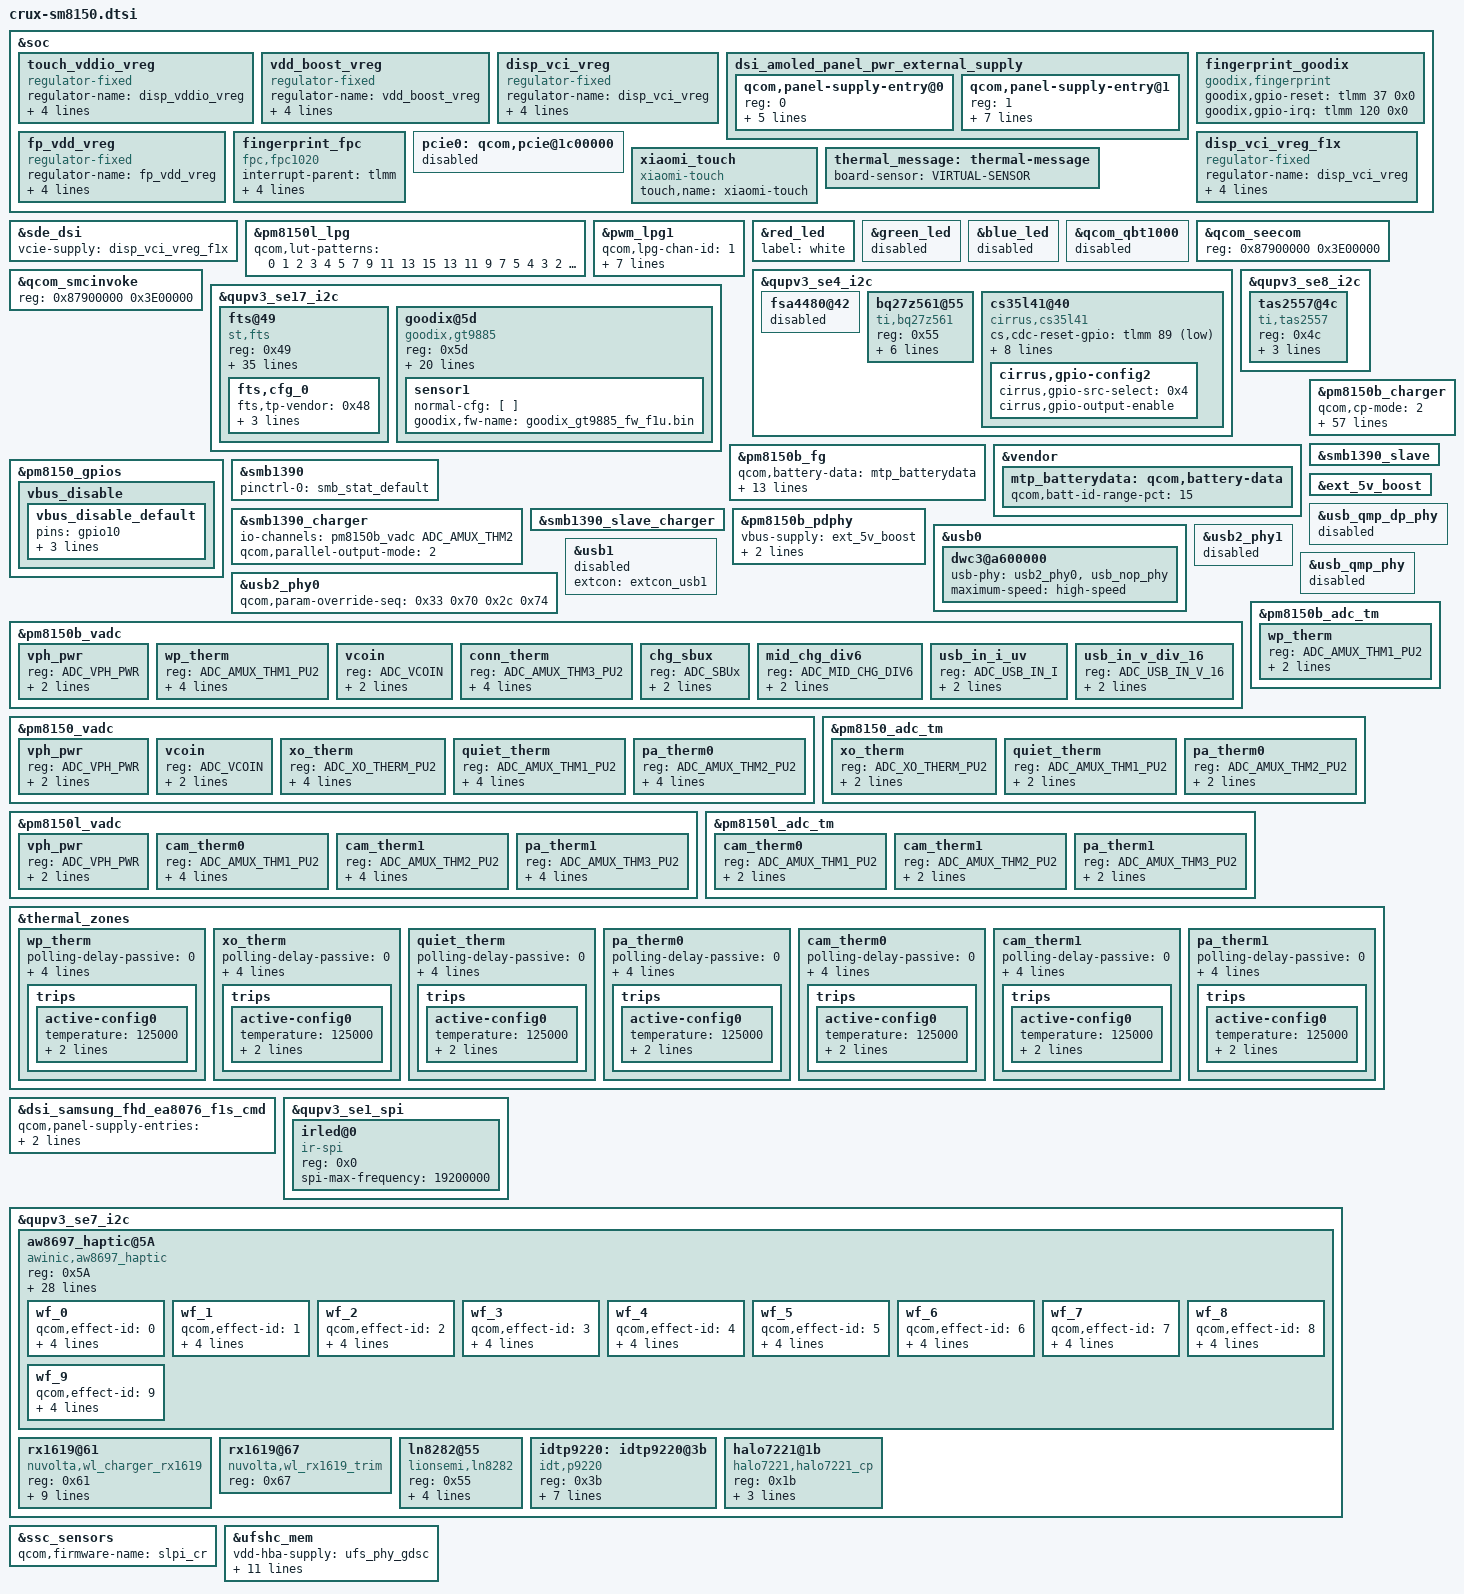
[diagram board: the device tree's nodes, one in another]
/*
this file is for attribution only of andromeda
And public attribution of xiaomi platforms(like F1X and so and)
*/

#include "crux-pinctrl.dtsi"
#include "xiaomi-sdx50-sm8150-common.dtsi"

#include "crux-sm8150-camera-sensor-mtp.dtsi"

&soc {
	touch_vddio_vreg: touch_vddio_vreg {
		compatible = "regulator-fixed";
		regulator-name = "disp_vddio_vreg";
		startup-delay-us = <4000>;
		enable-active-high;
		regulator-boot-on;
		gpio = <&tlmm 31 0>;
	 };
	vdd_boost_vreg: vdd_boost_vreg {
		compatible = "regulator-fixed";
		regulator-name = "vdd_boost_vreg";
		startup-delay-us = <4000>;
		enable-active-high;
		regulator-always-on;
		gpio = <&pm8150b_gpios 5 0>;
	 };
	disp_vci_vreg: disp_vci_vreg {
		compatible = "regulator-fixed";
		regulator-name = "disp_vci_vreg";
		start-delay-us = <4000>;
		enable-active-high;
		regulator-boot-on;
		gpio = <&tlmm 7 0>;
	};

	dsi_amoled_panel_pwr_external_supply: dsi_amoled_panel_pwr_external_supply {
		#address-cells = <1>;
		#size-cells = <0>;

		qcom,panel-supply-entry@0 {
			reg = <0>;
			qcom,supply-name = "vddio";
			qcom,supply-min-voltage = <1800000>;
			qcom,supply-max-voltage = <1800000>;
			qcom,supply-enable-load = <62000>;
			qcom,supply-disable-load = <80>;
			//qcom,supply-post-on-sleep = <20>;
		};

		qcom,panel-supply-entry@1 {
			reg = <1>;
			qcom,supply-name = "vcie";
			qcom,supply-min-voltage = <3000000>;
			qcom,supply-max-voltage = <3000000>;
			qcom,supply-enable-load = <62000>;
			qcom,supply-disable-load = <80>;
			qcom,supply-post-on-sleep = <10>;
			qcom,supply-pre-off-sleep = <10>;
		};
	};
	fingerprint_goodix {
		compatible = "goodix,fingerprint";
		goodix,gpio-reset = <&tlmm 37 0x0>;
		goodix,gpio-irq = <&tlmm 120 0x0>;
		/* fp-gpio-pwr = <&tlmm 125 0>; */
		status = "ok";
	};
	fp_vdd_vreg: fp_vdd_vreg {
		compatible = "regulator-fixed";
		regulator-name = "fp_vdd_vreg";
		startup-delay-us = <4000>;
		enable-active-high;
		gpio = <&tlmm 125 0>;
		regulator-always-on;
	};
	fingerprint_fpc {
		status = "ok";
		compatible = "fpc,fpc1020";
		interrupt-parent = <&tlmm>;
		interrupts = <118 0x0>;
		fpc,gpio_irq = <&tlmm 118 0x0>;
		/* fpc,enable-on-boot; */
		/* fpc,enable-wakeup;  */

		pinctrl-names = "fpc1020_reset_reset",
			"fpc1020_reset_active";

		pinctrl-0 = <&msm_gpio_119>;
		pinctrl-1 = <&msm_gpio_119_output_high>;
	};
	pcie0: qcom,pcie@1c00000 {
		status = "disabled";
	};

	disp_vci_vreg_f1x: disp_vci_vreg_f1x {
		compatible = "regulator-fixed";
		regulator-name = "disp_vci_vreg";
		start-delay-us = <4000>;
		enable-active-high;
		regulator-boot-on;
		gpio = <&tlmm 21 0>;
	};
	xiaomi_touch {
		compatible = "xiaomi-touch";
		status = "ok";
		touch,name = "xiaomi-touch";
	};
	thermal_message: thermal-message {
		board-sensor = "VIRTUAL-SENSOR";
	};
};

&sde_dsi {
	vcie-supply = <&disp_vci_vreg_f1x>;
};

&pm8150l_lpg {
	qcom,lut-patterns = <0 1 2 3 4 5 7 9 11 13 15
				13 11 9 7 5 4 3 2 1 0>;
};

&pwm_lpg1 {
	qcom,lpg-chan-id = <1>;
	qcom,ramp-step-ms = <100>;
	qcom,ramp-pause-hi-count = <2>;
	qcom,ramp-pause-lo-count = <2>;
	qcom,ramp-low-index = <0>;
	qcom,ramp-high-index = <20>;
	qcom,ramp-from-low-to-high;
	qcom,ramp-pattern-repeat;
};

&red_led {
	label = "white";
};

&green_led {
	status = "disabled";
};

&blue_led {
	status = "disabled";
};

&qcom_qbt1000 {
	status = "disabled";
};

&qcom_seecom {
	reg = <0x87900000 0x3E00000>;
};

&qcom_smcinvoke {
	reg = <0x87900000 0x3E00000>;
};

&qupv3_se4_i2c {
	status = "ok";

	fsa4480@42 {
		status = "disabled";
	};
};

&qupv3_se8_i2c {
	status = "ok";
	/*smart PA*/
	tas2557@4c{
		compatible = "ti,tas2557";
		reg = <0x4c>;
		//ti,cdc-reset-gpio = <&tlmm 59 0>;
		ti,irq-gpio = <&tlmm 115 0>;
		ti,i2s-bits = <16>;
		ti,bypass-tmax = <0>;
	};
};

&qupv3_se17_i2c {
	status = "ok";
	fts@49 {
		compatible = "st,fts";
		reg = <0x49>;
		interrupt-parent = <&tlmm>;
		interrupts = <122 0x2008>;
		pinctrl-names = "pmx_ts_active", "pmx_ts_suspend";
		pinctrl-0 = <&ts_active>;
		pinctrl-1 = <&ts_int_suspend &ts_reset_suspend>;
		avdd-supply = <&pm8150l_l1>;
		vdd-supply = <&touch_vddio_vreg>;
		fts,pwr-reg-name = "avdd";
		fts,bus-reg-name = "vdd";
		fts,irq-gpio = <&tlmm 122 0x2008>;
		fts,irq-gpio-name = "fts_irq";
		fts,reset-gpio-enable;
		fts,reset-gpio = <&tlmm 12 0x00>;
		fts,reset-gpio-name = "fts_rst";
		fts,irq-flags = <0x2008>; /* IRQF_ONESHOT | IRQF_TRIGGER_LOW */
		fts,x-max = <1080>;
		fts,y-max = <2340>;
		fts,default-fw-name = "st_fts_f1x.ftb";
		fts,config-array-size = <1>;
		fts,dump-click-count;
		fts,touch-up-threshold-min = <40>;
		fts,touch-up-threshold-max = <120>;
		fts,touch-up-threshold-def = <80>;
		fts,touch-tolerance-min = <5>;
		fts,touch-tolerance-max = <35>;
		fts,touch-tolerance-def = <25>;
		fts,edgefilter-leftrigt-def = <45>;
		fts,edgefilter-topbottom-def = <0>;
		fts,edgefilter-top-ingamemode = <65>;
		fts,edgefilter-bottom-ingamemode = <0>;
		fts,edgefilter-area-step1 = <100>;
		fts,edgefilter-area-step2 = <150>;
		fts,edgefilter-area-step3 = <250>;
		fts,touch-idletime-min = <0>;
		fts,touch-idletime-max = <12750>;
		fts,touch-idletime-def = <12450>;
		fts,cfg_0 {
			fts,tp-vendor = <0x48>;
			fts,fw-name = "st_fts_f1x.ftb";
			fts,limit-name = "stm_fts_production_limits.csv";
			fts,clicknum-file-name = "fts+sdc";
		};
	};
	goodix@5d {
		compatible = "goodix,gt9885";
		reg = <0x5d>;
		status = "ok";
		interrupt-parent = <&tlmm>;
		interrupts = <122 0x2800>;
		vtouch-source-supply = <&vdd_boost_vreg>;
		vtouch-supply = <&touch_vddio_vreg>;
		iotouch-supply = <&pm8150l_l1>;
		vtouch-load = <600000>;
		pinctrl-names = "pmx_ts_active","pmx_ts_suspend";
		pinctrl-0 = <&ts_active>;
		pinctrl-1 = <&ts_int_suspend &ts_reset_suspend>;
		goodix,reset-gpio = <&tlmm 12 0x0>;
		goodix,irq-gpio = <&tlmm 122 0x2800>;
		goodix,irq-flags = <2>; /* 1:trigger rising, 2:trigger falling;*/
		goodix,panel-max-id = <10>;
		goodix,panel-max-x = <1079>;
		goodix,panel-max-y = <2339>;
		goodix,panel-max-w = <127>;
		goodix,panel-max-p = <127>;
		goodix,panel-max-fod = <127>;
	/*	goodix,panel-key-map = <158 172 217>; */ /*KEY_BACK, KEY_HOMEPAGE, KEY_SEARCH*/
		goodix,power-on-delay-us = <300000>; /*300ms*/
		goodix,power-off-delay-us = <5000>;
		goodix,cfg-name = "goodix_gt9885_cfg_f1u.bin";
	/*	goodix,swap-axis; */
	/*	goodix,pen-enable; */
	/*	goodix,key-of-pen = <331 332>; */ /*BTN_STYLUS, BTN_STYLUS2*/
		sensor1 {
				normal-cfg = [
				];
				goodix,fw-name = "goodix_gt9885_fw_f1u.bin";
		};
	};
};

&pm8150b_fg {
	qcom,battery-data = <&mtp_batterydata>;
	qcom,rapid-soc-dec-en;
	qcom,fg-sys-term-current = <(-300)>;
	qcom,fg-cutoff-voltage = <3400>;
	qcom,fg-cutoff-current = <200>;
	qcom,fg-empty-voltage = <3100>;
	qcom,fg-batt-temp-delta = <6>;
	qcom,fg-force-load-profile;
	/* ESR fast calibration */
	qcom,fg-esr-timer-chg-fast = <0 7>;
	qcom,fg-esr-timer-dischg-fast = <0 7>;
	qcom,fg-esr-timer-chg-slow = <0 96>;
	qcom,fg-esr-timer-dischg-slow = <0 96>;
	qcom,fg-esr-cal-soc-thresh = <26 230>;
	qcom,fg-esr-cal-temp-thresh = <10 40>;
};

&vendor {
	mtp_batterydata: qcom,battery-data {
		qcom,batt-id-range-pct = <15>;
		#include "batterydata-F1-atl-3300mah.dtsi"
		#include "batterydata-F1-coslight-3300mah.dtsi"
		#include "fg-gen4-batterydata-alium-3600mah.dtsi"
	};
};

&pm8150_gpios {
	vbus_disable {
		vbus_disable_default: vbus_disable_default {
			pins = "gpio10";
			function = "normal";
			output-low;
			power-source = <1>;	/* 1.8V input supply */
		};
	};
};

&pm8150b_charger {
	qcom,cp-mode = <2>;
	qcom,sec-charger-config = <1>;
	qcom,usb-icl-ua = <4000000>;
	qcom,fcc-max-ua = <8000000>;
	qcom,fv-max-uv = <4480000>;
	qcom,dc-icl-ua = <500000>;
	qcom,auto-recharge-vbat-mv = <4380>;
	qcom,step-charging-enable;
	qcom,sw-jeita-enable;
	qcom,chg-term-src = <1>;
	qcom,chg-term-current-ma = <(-220)>;
	qcom,chg-term-base-current-ma = <50>;
	qcom,thermal-mitigation = <3000000 2800000 2600000 2400000 2200000 2100000 2000000
				   1800000 1600000 1500000 1400000 1200000 1000000 900000
				   800000 500000>;
	qcom,thermal-mitigation-icl
				= <2800000 2700000 2600000 2400000 2400000 2400000 2400000
				   2400000 2400000 2100000 1900000 1700000 1500000 1300000
				   1000000 750000>;
	qcom,thermal-mitigation-dcp
				= <1800000 1800000 1800000 1800000 1800000 1800000 1800000
				   1800000 1800000 1700000 1600000 1400000 1200000 1100000
				   1100000 1000000>;
	qcom,thermal-mitigation-qc2
				= <1500000 1500000 1500000 1500000 1450000 1400000 1350000
				   1300000 1300000 1200000 1000000 900000 850000 750000
				   650000 500000>;
	qcom,thermal-fcc-qc3-normal
				= <3200000 3000000 2800000 2600000 2500000 2400000 2300000
				   2200000 2100000 1800000 1600000 1400000 1200000 1000000
				   750000 750000>;
	qcom,thermal-fcc-qc3-cp
				= <3600000 3600000 3600000 3600000 3200000 3200000 3200000
				   3200000 3100000 2800000 2400000 2200000 2000000 1300000
				   750000 700000>;
	qcom,thermal-fcc-qc3-classb-cp
				= <4800000 4700000 4600000 4500000 4400000 4200000 4200000
				   4200000 4000000 3600000 3400000 3200000 3000000 2200000
				   1000000 700000>;
	qcom,thermal-mitigation-pd-base
				= <4000000 3600000 3200000 2800000 2800000 2800000 2800000
				   2800000 2800000 2400000 2400000 2000000 1600000 1300000
				   1000000 500000>;
	qcom,thermal-fcc-pps-cp
				= <8000000 7500000 7000000 6500000 6000000 5500000 5350000
				   4500000 4000000 3500000 3000000 3000000 3000000 2000000
				   1500000 100000>;
	qcom,thermal-mitigation-dc
				= <3100000 2200000 1800000 1600000 1400000 1200000 1100000
				   1000000 900000  800000  700000  600000  500000  400000
				   300000  200000>;
	qcom,thermal-mitigation-epp
				= <1200000 1200000 1200000 1100000 1100000 1000000 1000000
				   1000000 900000  700000  700000  600000  500000  400000
				   300000  200000>;
	qcom,thermal-mitigation-bpp-qc3
				= <1400000 1300000 1200000 1200000 1100000 1000000 900000
				   800000  700000  700000  700000  600000  500000  400000
				   300000  200000>;
	qcom,thermal-mitigation-bpp-qc2
				= <1100000 1100000 1100000 1100000 1100000 1000000 1000000
				   1000000 700000  700000  700000  600000  500000  400000
				   300000  200000>;
	qcom,thermal-mitigation-bpp
				= <700000 700000 700000 700000 700000 700000 700000
				   700000 700000  600000  600000  500000  400000 300000
				   200000  200000>;
	qcom,thermal-mitigation-dc-20w
				= <2200000 1400000 1300000 1200000 700000 600000 500000
				   400000 400000  400000  400000  400000  400000  400000
				   400000  400000>;

	io-channels = <&pm8150b_vadc ADC_MID_CHG_DIV6>,
		      <&pm8150b_vadc ADC_USB_IN_V_16>,
		      <&pm8150b_vadc ADC_USB_IN_I>,
		      <&pm8150b_vadc ADC_SBUx>,
		      <&pm8150b_vadc ADC_VPH_PWR>,
		      <&pm8150b_vadc ADC_CHG_TEMP>,
		      <&pm8150b_vadc ADC_AMUX_THM3_PU2>;

	io-channel-names = "mid_voltage",
			   "usb_in_voltage",
			   "usb_in_current",
			   "sbux_res",
			   "vph_voltage",
			   "chg_temp",
			   "conn_therm";

	qcom,battery-data = <&mtp_batterydata>;
	dpdm-supply = <&usb2_phy0>;
	qcom,distinguish-qc-class-ab;
	qcom,wd-bark-time-secs = <16>;
	qcom,support-wireless;
	qcom,support-conn-therm;
	qcom,support-ext-fg;

	vbus-disable-gpio = <&pm8150_gpios 10 GPIO_ACTIVE_HIGH>;

	pinctrl-names = "default";
	pinctrl-0 = <&vbus_disable_default>;
};

&smb1390 {
	pinctrl-names = "default";
	pinctrl-0 = <&smb_stat_default>;
	status = "ok";
};

&smb1390_charger {
	io-channels = <&pm8150b_vadc ADC_AMUX_THM2>;
	io-channel-names = "smb1390_therm";
	qcom,parallel-output-mode = <2>;
	status = "ok";
};

&smb1390_slave {
	status = "ok";
};

&smb1390_slave_charger {
	status = "ok";
};



&ext_5v_boost {
	status = "ok";
};

&pm8150b_pdphy {
	vbus-supply = <&ext_5v_boost>;
	mi,pd_curr_limit = <1>;
	mi,pd_max_curr_limit = <4000000>;
};

&usb0 {
	dwc3@a600000 {
		usb-phy = <&usb2_phy0>, <&usb_nop_phy>;
		maximum-speed = "high-speed";
	};
};

&usb2_phy0 {
	qcom,param-override-seq =
		<0x33 0x70
		 0x2c 0x74>;
};

&usb_qmp_dp_phy {
	status = "disabled";
};

&usb1 {
	extcon = <&extcon_usb1>;
	status = "disabled";
};

&usb2_phy1 {
	status = "disabled";
};

&usb_qmp_phy {
	status = "disabled";
};

&pm8150b_vadc {
	vph_pwr {
		reg = <ADC_VPH_PWR>;
		label = "vph_pwr";
		qcom,pre-scaling = <1 3>;
	};

	wp_therm {
		reg = <ADC_AMUX_THM1_PU2>;
		label = "wp_therm";
		qcom,ratiometric;
		qcom,hw-settle-time = <200>;
		qcom,pre-scaling = <1 1>;
	};

	vcoin {
		reg = <ADC_VCOIN>;
		label = "vcoin";
		qcom,pre-scaling = <1 3>;
	};

	conn_therm {
		reg = <ADC_AMUX_THM3_PU2>;
		label = "conn_therm";
		qcom,ratiometric;
		qcom,hw-settle-time = <200>;
		qcom,pre-scaling = <1 1>;
	};

	chg_sbux {
		reg = <ADC_SBUx>;
		label = "chg_sbux";
		qcom,pre-scaling = <1 3>;
	};

	mid_chg_div6 {
		reg = <ADC_MID_CHG_DIV6>;
		label = "chg_mid";
		qcom,pre-scaling = <1 6>;
	};

	usb_in_i_uv {
		reg = <ADC_USB_IN_I>;
		label = "usb_in_i_uv";
		qcom,pre-scaling = <1 1>;
	};

	usb_in_v_div_16 {
		reg = <ADC_USB_IN_V_16>;
		label = "usb_in_v_div_16";
		qcom,pre-scaling = <1 16>;
	};
};

&pm8150_vadc {
	vph_pwr {
		reg = <ADC_VPH_PWR>;
		label = "vph_pwr";
		qcom,pre-scaling = <1 3>;
	};

	vcoin {
		reg = <ADC_VCOIN>;
		label = "vcoin";
		qcom,pre-scaling = <1 3>;
	};

	xo_therm {
		reg = <ADC_XO_THERM_PU2>;
		label = "xo_therm";
		qcom,ratiometric;
		qcom,hw-settle-time = <200>;
		qcom,pre-scaling = <1 1>;
	};

	quiet_therm {
		reg = <ADC_AMUX_THM1_PU2>;
		label = "quiet_therm";
		qcom,ratiometric;
		qcom,hw-settle-time = <200>;
		qcom,pre-scaling = <1 1>;
	};

	pa_therm0 {
		reg = <ADC_AMUX_THM2_PU2>;
		label = "pa_therm0";
		qcom,ratiometric;
		qcom,hw-settle-time = <200>;
		qcom,pre-scaling = <1 1>;
	};
};

&pm8150l_vadc {
	vph_pwr {
		reg = <ADC_VPH_PWR>;
		label = "vph_pwr";
		qcom,pre-scaling = <1 3>;
	};

	cam_therm0 {
		reg = <ADC_AMUX_THM1_PU2>;
		label = "cam_therm0";
		qcom,ratiometric;
		qcom,hw-settle-time = <200>;
		qcom,pre-scaling = <1 1>;
	};

	cam_therm1 {
		reg = <ADC_AMUX_THM2_PU2>;
		label = "cam_therm1";
		qcom,ratiometric;
		qcom,hw-settle-time = <200>;
		qcom,pre-scaling = <1 1>;
	};

	pa_therm1 {
		reg = <ADC_AMUX_THM3_PU2>;
		label = "pa_therm1";
		qcom,ratiometric;
		qcom,hw-settle-time = <200>;
		qcom,pre-scaling = <1 1>;
	};
};

&pm8150b_adc_tm {
	wp_therm {
		reg = <ADC_AMUX_THM1_PU2>;
		qcom,ratiometric;
		qcom,hw-settle-time = <200>;
	};
};

&pm8150_adc_tm {
	xo_therm {
		reg = <ADC_XO_THERM_PU2>;
		qcom,ratiometric;
		qcom,hw-settle-time = <200>;
	};
	quiet_therm {
		reg = <ADC_AMUX_THM1_PU2>;
		qcom,ratiometric;
		qcom,hw-settle-time = <200>;
	};

	pa_therm0 {
		reg = <ADC_AMUX_THM2_PU2>;
		qcom,ratiometric;
		qcom,hw-settle-time = <200>;
	};
};

&pm8150l_adc_tm {
	cam_therm0 {
		reg = <ADC_AMUX_THM1_PU2>;
		qcom,ratiometric;
		qcom,hw-settle-time = <200>;
	};

	cam_therm1 {
		reg = <ADC_AMUX_THM2_PU2>;
		qcom,ratiometric;
		qcom,hw-settle-time = <200>;
	};

	pa_therm1 {
		reg = <ADC_AMUX_THM3_PU2>;
		qcom,ratiometric;
		qcom,hw-settle-time = <200>;
	};
};

&thermal_zones {
	wp_therm {
		polling-delay-passive = <0>;
		polling-delay = <0>;
		thermal-governor = "user_space";
		thermal-sensors = <&pm8150b_adc_tm ADC_AMUX_THM1_PU2>;
		trips {
			active-config0 {
				temperature = <125000>;
				hysteresis = <1000>;
				type = "passive";
			};
		};
	};

	xo_therm {
		polling-delay-passive = <0>;
		polling-delay = <0>;
		thermal-governor = "user_space";
		thermal-sensors = <&pm8150_adc_tm ADC_XO_THERM_PU2>;
		trips {
			active-config0 {
				temperature = <125000>;
				hysteresis = <1000>;
				type = "passive";
			};
		};
	};

	quiet_therm {
		polling-delay-passive = <0>;
		polling-delay = <0>;
		thermal-governor = "user_space";
		thermal-sensors = <&pm8150_adc_tm ADC_AMUX_THM1_PU2>;
		trips {
			active-config0 {
				temperature = <125000>;
				hysteresis = <1000>;
				type = "passive";
			};
		};
	};

	pa_therm0 {
		polling-delay-passive = <0>;
		polling-delay = <0>;
		thermal-governor = "user_space";
		thermal-sensors = <&pm8150_adc_tm ADC_AMUX_THM2_PU2>;
		trips {
			active-config0 {
				temperature = <125000>;
				hysteresis = <1000>;
				type = "passive";
			};
		};
	};

	cam_therm0 {
		polling-delay-passive = <0>;
		polling-delay = <0>;
		thermal-governor = "user_space";
		thermal-sensors = <&pm8150l_adc_tm ADC_AMUX_THM1_PU2>;
		trips {
			active-config0 {
				temperature = <125000>;
				hysteresis = <1000>;
				type = "passive";
			};
		};
	};

	cam_therm1 {
		polling-delay-passive = <0>;
		polling-delay = <0>;
		thermal-governor = "user_space";
		thermal-sensors = <&pm8150l_adc_tm ADC_AMUX_THM2_PU2>;
		trips {
			active-config0 {
				temperature = <125000>;
				hysteresis = <1000>;
				type = "passive";
			};
		};
	};

	pa_therm1 {
		polling-delay-passive = <0>;
		polling-delay = <0>;
		thermal-governor = "user_space";
		thermal-sensors = <&pm8150l_adc_tm ADC_AMUX_THM3_PU2>;
		trips {
			active-config0 {
				temperature = <125000>;
				hysteresis = <1000>;
				type = "passive";
			};
		};
	};
};

&qupv3_se4_i2c {
	status = "ok";
	bq27z561@55 {
		compatible = "ti,bq27z561";
		reg = <0x55>;
		bq,charge-full-design = <4000000>;
		bq,recharge-voltage   = <4380>;
		bq,soc_decimal_rate = <
			0  38
			10 35
			20 33
			30 33
			40 33
			50 33
			60 33
			70 30
			80 25
			90 20
			95 10
			99  5 >;
		bq,cold_thermal_seq = <
			1      0  100 1700
			2  (-300)   0 1000 >;
	};

	fsa4480@42 {
		status = "disabled";
	};

	cs35l41@40 {
		#sound-dai-cells = <1>;
		compatible = "cirrus,cs35l41";
		cs,cdc-reset-gpio = <&tlmm 89 0x01>;
		reg = <0x40>;
		pinctrl-names = "cs35l41_irq_default";
		pinctrl-0 = <&cs35l41_int_default>;
		interrupt-parent = <&tlmm>;
		interrupts = <10 8>;

		cirrus,temp-warn_threshold = <3>;
		cirrus,boost-peak-milliamp = <4000>;
		cirrus,boost-ind-nanohenry = <1000>;
		cirrus,boost-cap-microfarad = <15>;
		cirrus,gpio-config2 {
			cirrus,gpio-src-select = <0x4>;
			cirrus,gpio-output-enable;
		};
		/*
		VA-supply = <&dummy_vreg>;
		VP-supply = <&dummy_vreg>;
		interrupt-parent = <&tlmm>;
		interrupts = <11 8>;
		reset-gpios = <&tlmm 7 0x01>;
		VA-supply = <&pm8998_s4>;
		VP-supply = <&audio_vsys>;
		cirrus,boost-peak-milliamp = <4500>;
		cirrus,boost-ind-nanohenry = <1000>;
		cirrus,boost-cap-microfarad = <15>;
		cirrus,gpio-config2 {
			cirrus,gpio-src-select = <0x4>;
			cirrus,gpio-output-enable;
		};
		*/
	};
};

&dsi_samsung_fhd_ea8076_f1s_cmd {
	qcom,panel-supply-entries = <&dsi_amoled_panel_pwr_external_supply>;
	/* IRQF_ONESHOT | IRQF_TRIGGER_FALLING */
	qcom,esd-err-irq-gpio = <&tlmm 101 0x2002>;
};

//&dsi_visionox_fhd_rm692a9_f1u_cmd {
//	qcom,panel-supply-entries = <&dsi_amoled_panel_pwr_external_supply>;
	/* IRQF_ONESHOT | IRQF_TRIGGER_FALLING */
//	qcom,esd-err-irq-gpio = <&tlmm 101 0x2002>;
//};

&qupv3_se1_spi {
	status = "ok";
	irled@0 {
		compatible = "ir-spi";
		reg = <0x0>;
		status = "ok";
		spi-max-frequency = <19200000>;
	};
};

&qupv3_se7_i2c {
	status = "ok";
	aw8697_haptic@5A {
		compatible = "awinic,aw8697_haptic";
		reg = <0x5A>;
		reset-gpio = <&tlmm 6 0>;
		irq-gpio = <&tlmm 27 0>;
		vib_mode = < 0 >;   /*mode:   RAM mode->0; CONT mode -> 1*/
		vib_f0_pre = < 1700 >;
		vib_f0_cali_percen = < 7 >;
		vib_cont_drv_lev = < 88 >;
		vib_cont_drv_lvl_ov = < 88 >;
		vib_cont_td = < 0xf06c >;
		vib_cont_zc_thr = < 0x08f8 >;  /*hq 0x08F8 */
		vib_cont_num_brk = < 3 >;
		vib_f0_coeff = < 260 >; /*Don't modify it    2.604167*/
		vib_f0_trace_parameter = < 9 3 1 31 >;
		vib_bemf_config = < 0 0x08 0x03 0xf8 >;
		vib_sw_brake = < 0x2c >;
		vib_tset = < 0x12 >;
		vib_r_spare = < 0x68 >;
		vib_bstdbg = < 0x30 0xeb 0xd4 0 0 0 >;
		vib_effect_id_boundary = < 10 >;
		vib_effect_max = < 170 >;
		vib_trig_config = < 0 1 0 1 2
						0 1 0 1 2
						0 1 0 1 2 >;
		vib_bst_vol_default = < 0x1b >;
		vib_bst_vol_ram = < 0x1b >;
		vib_bst_vol_rtp = < 0x16 >;
		vib_rtp_time = < 20 20 20 20 20 20 20 20 20000 15000
				 15000 20000 25000 15000 30000 25000 20000 20000 20000 20000
				 20000 20000 20000 20000 20000 20000 20000 20000 20000 20000
				 20000 20000 20000 20000 20000 20000 20000 20000 20000 20000
				 20000 20000 20000 20000 20000 20000 20000 20000 20000 20000
				 20000 20000 20000 20000 20000 20000 20000 20000 20000 20000
				 20000 20000 20000 20000 20000 20000 20000 20000 20000 20000
				 20000 20000 20000 20000 20000 20000 20000 20000 20000 20000
				 20000 20000 20000 20000 20000 20000 20000 20000 20000 20000
				 20000 20000 20000 20000 20000 20000 20000 20000 20000 20000
				 20000 20000 20000 20000 20000 20000 20000 20000 20000 20000
				 20000 20000 20000 20000 20000 20000 20000 20000 20000 20000
				 20000 20000 20000 20000 20000 20000 20000 20000 20000 20000
				 20000 20000 20000 20000 20000 20000 20000 20000 20000 20000
				 20000 20000 20000 20000 20000 20000 20000 20000 20000 20000
				 20000 20000 20000 20000 20000 20000 20000 20000 20000 20000
				 20000 20000 20000 20000 20000 20000 20000 20000 20000 20000
				 20000 20000 20000 20000 20000 >;
		pinctrl-names = "aw8697_reset_reset","aw8697_reset_active","aw8697_interrupt_active";
		pinctrl-0 = <&msm_gpio_6>;
		pinctrl-1 = <&msm_gpio_6_output_high>;
		pinctrl-2 = <&msm_gpio_27>;
		status = "ok";
		wf_0 {
			/*CLICK*/
			qcom,effect-id = <0>;
			qcom,wf-vmax-mv = <3600>;
			qcom,wf-pattern = [3e 3e];
			qcom,wf-brake-pattern = [02 01 00 00];
			qcom,wf-play-rate-us = <20000>;
		};
		wf_1 {
			/*DOUBLE CLICK*/
			qcom,effect-id = <1>;
			qcom,wf-vmax-mv = <3600>;
			qcom,wf-pattern = [7e 3e];
			qcom,wf-brake-pattern = [03 01 00 00];
			qcom,wf-play-rate-us = <20000>;
		};
		wf_2 {
			/*TICK*/
			qcom,effect-id = <2>;
			qcom,wf-vmax-mv = <3600>;
			qcom,wf-pattern = [7e 3e];
			qcom,wf-brake-pattern = [02 01 00 00];
			qcom,wf-play-rate-us = <20000>;
		};
		wf_3 {
			/*THUD*/
			qcom,effect-id = <3>;
			qcom,wf-vmax-mv = <3600>;
			qcom,wf-pattern = [3e 3e];
			qcom,wf-brake-pattern = [02 01 00 00];
			qcom,wf-play-rate-us = <20000>;
		};
		wf_4 {
			/*POP*/
			qcom,effect-id = <4>;
			qcom,wf-vmax-mv = <3600>;
			qcom,wf-pattern = [3e 3e];
			qcom,wf-brake-pattern = [02 01 00 00];
			qcom,wf-play-rate-us = <28000>;
		};
		wf_5 {
			/*HEAVY CLICK*/
			qcom,effect-id = <5>;
			qcom,wf-vmax-mv = <3600>;
			qcom,wf-pattern = [7e 7e 7e];
			qcom,wf-brake-pattern = [03 03 01 00];
			qcom,wf-play-rate-us = <20000>;
		};
		wf_6 {
			/*id 6*/
			qcom,effect-id = <6>;
			qcom,wf-vmax-mv = <3600>;
			qcom,wf-pattern = [3e 3e];
			qcom,wf-brake-pattern = [02 01 00 00];
			qcom,wf-play-rate-us = <20000>;
		};
		wf_7 {
			/*id 7*/
			qcom,effect-id = <7>;
			qcom,wf-vmax-mv = <3600>;
			qcom,wf-pattern = [3e 3e];
			qcom,wf-brake-pattern = [02 01 00 00];
			qcom,wf-play-rate-us = <20000>;
		};
		wf_8 {
			/*id 8*/
			qcom,effect-id = <8>;
			qcom,wf-vmax-mv = <3600>;
			qcom,wf-pattern = [3e 3e];
			qcom,wf-brake-pattern = [02 01 00 00];
			qcom,wf-play-rate-us = <20000>;
		};
		wf_9 {
			/*id 9*/
			qcom,effect-id = <9>;
			qcom,wf-vmax-mv = <3600>;
			qcom,wf-pattern = [3e 3e];
			qcom,wf-brake-pattern = [02 01 00 00];
			qcom,wf-play-rate-us = <20000>;
		};
	};

	rx1619@61 {
		compatible = "nuvolta,wl_charger_rx1619";
		reg = <0x61>;
		rx,irq_gpio = <&tlmm 90 0x00>;
		rx,tx_on_gpio = <&tlmm 130 0x00>;
		rx,wpc-det = <&pm8150b_gpios 7 GPIO_ACTIVE_HIGH>;
		rx,enable = <&tlmm 7 0x00>;
		pinctrl-names = "default","nu_active","nu_suspend";
		pinctrl-0 = <&power_good_default>;
		pinctrl-1 = <&nu_int_active &txon_enable_active &nu_sleep_active>;
		pinctrl-2 = <&nu_int_suspend &txon_enable_suspend &nu_sleep_suspend>;
	};
	rx1619@67 {
		compatible = "nuvolta,wl_rx1619_trim";
		reg = <0x67>;
	};
	ln8282@55 {
		compatible = "lionsemi,ln8282";
		reg = <0x55>;
		ln,enable = <&tlmm 41 0x00>;
		ln,irq = <&tlmm 92 0x00>;
		pinctrl-names = "ln8282_active","ln8282_suspend";
		pinctrl-0 = <&ln8282_enable_active>;
		pinctrl-1 = <&ln8282_enable_suspend>;
	};
	idtp9220: idtp9220@3b {
		compatible = "idt,p9220";
		reg = <0x3b>;
		idt,irq = <&tlmm 90 0x00>;
		idt,enable = <&tlmm 7 0x00>;
		idt,reverse-enable = <&tlmm 130 0x00>;
		idt,wpc-det = <&pm8150b_gpios 7 GPIO_ACTIVE_HIGH>;
		pinctrl-names = "default", "idt_active", "idt_suspend";
		pinctrl-0 = <&power_good_default>;
		pinctrl-1 = <&idt_int_active &idt_enable_active>;
		pinctrl-2 = <&idt_int_suspend &idt_enable_suspend>;
	};
	halo7221@1b {
		compatible = "halo7221,halo7221_cp";
		reg = <0x1b>;
		halo,enable = <&tlmm 41 0x00>;
		pinctrl-names = "halo7221_active","halo7221_suspend";
		pinctrl-0 = <&halo7221_enable_active>;
		pinctrl-1 = <&halo7221_enable_suspend>;
	};
};

&ssc_sensors {
	qcom,firmware-name = "slpi_cr";
};

&ufshc_mem {
	vdd-hba-supply = <&ufs_phy_gdsc>;
	vdd-hba-fixed-regulator;
	vcc-supply = <&pm8150_l10>;
	vcc-voltage-level = <2504000 2950000>;
	vcc-low-voltage-sup;
	vccq-supply = <&pm8150_l9>;
	vccq2-supply = <&pm8150_s4>;
	vcc-max-microamp = <750000>;
	vccq-max-microamp = <700000>;
	vccq2-max-microamp = <750000>;

	qcom,vddp-ref-clk-supply = <&pm8150_l9>;
	qcom,vddp-ref-clk-max-microamp = <100>;

	status = "ok";
};
